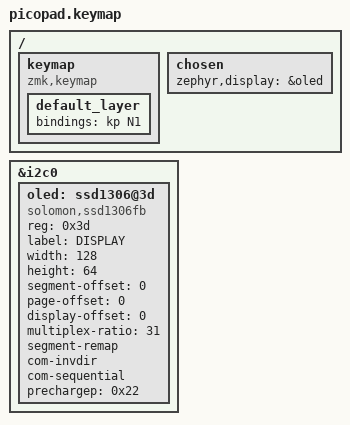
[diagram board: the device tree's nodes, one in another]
#include <behaviors.dtsi>
#include <dt-bindings/zmk/keys.h>

/ {
    keymap {
        compatible = "zmk,keymap";

        default_layer {
             bindings = < &kp N1 >;
            
        };
    };
};

&i2c0 {
    status = "okay";

    oled: ssd1306@3d {
        compatible = "solomon,ssd1306fb";                                     
        reg = <0x3d>;
        label = "DISPLAY";
        width = <128>;
        height = <64>;
        segment-offset = <0>;
        page-offset = <0>;
        display-offset = <0>;
        multiplex-ratio = <31>;
        segment-remap;
        com-invdir;
        com-sequential; 
        prechargep = <0x22>;
    };
};

/ {
    chosen {
        zephyr,display = &oled;
    };
}; 
